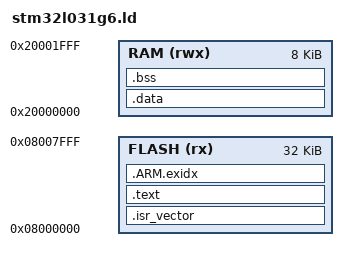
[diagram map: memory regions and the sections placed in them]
/* STM32L031G6: 32 KB flash, 8 KB RAM */
ENTRY(Reset_Handler)

MEMORY
{
    FLASH (rx)  : ORIGIN = 0x08000000, LENGTH = 32K
    RAM   (rwx) : ORIGIN = 0x20000000, LENGTH = 8K
}

_estack = ORIGIN(RAM) + LENGTH(RAM);

SECTIONS
{
    .isr_vector : { KEEP(*(.isr_vector)) } > FLASH

    .text :
    {
        *(.text*)
        *(.rodata*)
        . = ALIGN(4);
    } > FLASH

    .ARM.exidx : { *(.ARM.exidx*) . = ALIGN(4); } > FLASH
    _etext = .;

    .data : AT(_etext)
    {
        _sdata = .;
        *(.data*)
        . = ALIGN(4);
        _edata = .;
    } > RAM
    _sidata = LOADADDR(.data);

    .bss (NOLOAD) :
    {
        _sbss = .;
        *(.bss*)
        *(COMMON)
        . = ALIGN(4);
        _ebss = .;
    } > RAM
    end = _ebss;   /* heap start for newlib's sbrk */

    /* keep at least 1 KB for the stack */
    ASSERT(_ebss + 1024 <= _estack, "RAM overflow: less than 1 KB left for the stack")
}
